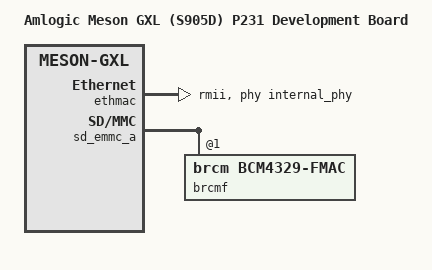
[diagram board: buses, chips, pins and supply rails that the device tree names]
// SPDX-License-Identifier: (GPL-2.0+ OR MIT)
/*
 * Copyright (c) 2016 Endless Computers, Inc.
 * Author: Carlo Caione <carlo@endlessm.com>
 */

/dts-v1/;

#include "meson-gxl-s905d.dtsi"
#include "meson-gx-p23x-q20x.dtsi"

/ {
	compatible = "amlogic,p231", "amlogic,s905d", "amlogic,meson-gxl";
	model = "Amlogic Meson GXL (S905D) P231 Development Board";
};

/* P231 has only internal PHY port */
&ethmac {
	phy-mode = "rmii";
	phy-handle = <&internal_phy>;
};

&sd_emmc_a {
	brcmf: wifi@1 {
		reg = <1>;
		compatible = "brcm,bcm4329-fmac";
	};
};
